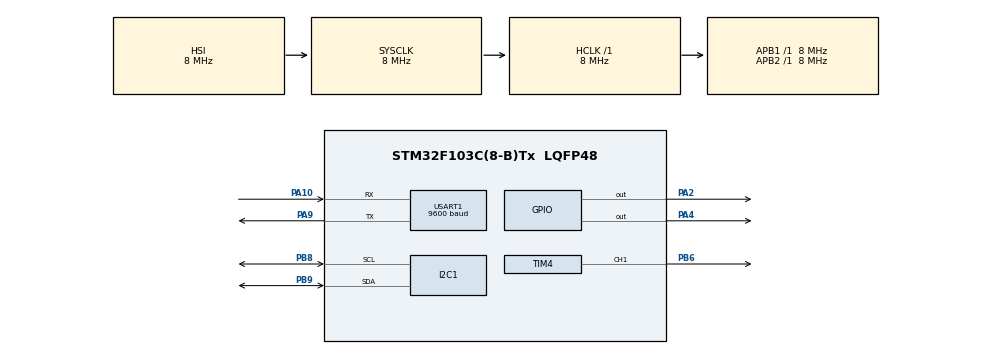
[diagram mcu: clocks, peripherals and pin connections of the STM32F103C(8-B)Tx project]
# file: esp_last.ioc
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Mcu.Family=STM32F1
Mcu.Name=STM32F103C(8-B)Tx
Mcu.Package=LQFP48
NVIC.FLASH_IRQn=true\:0\:0\:true\:false\:true\:true\:true
NVIC.I2C1_ER_IRQn=true\:0\:0\:false\:false\:true\:true\:true
NVIC.I2C1_EV_IRQn=true\:0\:0\:false\:false\:true\:true\:true
NVIC.PriorityGroup=NVIC_PRIORITYGROUP_4
NVIC.RCC_IRQn=true\:0\:0\:false\:false\:true\:true\:false
NVIC.TIM4_IRQn=true\:0\:0\:false\:false\:true\:true\:true
NVIC.USART1_IRQn=true\:0\:0\:false\:false\:true\:true\:true
PA10.Mode=Asynchronous
PA10.Signal=USART1_RX
PA13.Mode=Serial_Wire
PA13.Signal=SYS_JTMS-SWDIO
PA14.Mode=Serial_Wire
PA14.Signal=SYS_JTCK-SWCLK
PA2.Signal=GPIO_Output
PA4.Signal=GPIO_Output
PA9.Mode=Asynchronous
PA9.Signal=USART1_TX
PB6.Signal=S_TIM4_CH1
PB8.Mode=I2C
PB8.Signal=I2C1_SCL
PB9.Mode=I2C
PB9.Signal=I2C1_SDA
PD0-OSC_IN.Mode=HSE-External-Oscillator
PD0-OSC_IN.Signal=RCC_OSC_IN
PD1-OSC_OUT.Mode=HSE-External-Oscillator
PD1-OSC_OUT.Signal=RCC_OSC_OUT
ProjectManager.HeapSize=0x200
ProjectManager.StackSize=0x400
ProjectManager.TargetToolchain=MDK-ARM V5
RCC.AHBFreq_Value=8000000
RCC.APB1Freq_Value=8000000
RCC.APB1TimFreq_Value=8000000
RCC.APB2Freq_Value=8000000
RCC.APB2TimFreq_Value=8000000
RCC.HCLKFreq_Value=8000000
RCC.SYSCLKFreq_VALUE=8000000
RCC.USBFreq_Value=8000000
SH.S_TIM4_CH1.0=TIM4_CH1,PWM Generation1 CH1
TIM4.Channel-PWM\ Generation1\ CH1=TIM_CHANNEL_1
TIM4.ClockDivision=TIM_CLOCKDIVISION_DIV1
TIM4.Period=999
TIM4.Prescaler=19
TIM4.Pulse-PWM\ Generation1\ CH1=500
USART1.BaudRate=9600
USART1.VirtualMode=VM_ASYNC
VP_TIM4_VS_ClockSourceINT.Mode=Internal
board=custom

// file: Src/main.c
/* USER CODE BEGIN Header */
/**
  ******************************************************************************
  * @file           : main.c
  * @brief          : Main program body
  ******************************************************************************
  * @attention
  *
  * <h2><center>&copy; Copyright (c) 2019 STMicroelectronics.
  * All rights reserved.</center></h2>
  *
  * This software component is licensed by ST under BSD 3-Clause license,
  * the "License"; You may not use this file except in compliance with the
  * License. You may obtain a copy of the License at:
  *                        opensource.org/licenses/BSD-3-Clause
  *
  ******************************************************************************
  */
/* USER CODE END Header */

#include "main.h"

/* USER CODE BEGIN Includes */
#include "stm32f1xx_hal.h"
#include "esp8266.h"
#include "servo.h"
#include "write_lcd_func.h"
/* USER CODE END Includes */

I2C_HandleTypeDef hi2c1;

TIM_HandleTypeDef htim4;

//UART_HandleTypeDef huart1;

/* USER CODE BEGIN PV */
extern UART_HandleTypeDef huart1;
extern int complete;
/* USER CODE END PV */

void SystemClock_Config(void);
static void MX_GPIO_Init(void);
static void MX_I2C1_Init(void);
static void MX_USART1_UART_Init(void);
static void MX_TIM4_Init(void);

/* USER CODE BEGIN 0 */
extern uint8_t Rx_data;
/* USER CODE END 0 */

int main(void)
{

  /* MCU Configuration--------------------------------------------------------*/

  /* Reset of all peripherals, Initializes the Flash interface and the Systick. */
  HAL_Init();

  /* Configure the system clock */
  SystemClock_Config();

  /* Initialize all configured peripherals */
  MX_GPIO_Init();
  MX_I2C1_Init();
  MX_USART1_UART_Init();
  MX_TIM4_Init();
  /* USER CODE BEGIN 2 */
	send_intro_lcd();
	HAL_UART_Receive_IT(&huart1,	&Rx_data, 1);
	ESP_Init();
  /* USER CODE END 2 */

  /* Infinite loop */
  while (1)
  {

    /* USER CODE BEGIN 3 */
//		if(complete == 1)
		ESP_Read();
  }
  /* USER CODE END 3 */
}

void SystemClock_Config(void)
{
  RCC_OscInitTypeDef RCC_OscInitStruct = {0};
  RCC_ClkInitTypeDef RCC_ClkInitStruct = {0};

  /** Initializes the CPU, AHB and APB busses clocks
  */
  RCC_OscInitStruct.OscillatorType = RCC_OSCILLATORTYPE_HSI;
  RCC_OscInitStruct.HSIState = RCC_HSI_ON;
  RCC_OscInitStruct.HSICalibrationValue = RCC_HSICALIBRATION_DEFAULT;
  RCC_OscInitStruct.PLL.PLLState = RCC_PLL_NONE;
  if (HAL_RCC_OscConfig(&RCC_OscInitStruct) != HAL_OK)
  {
    Error_Handler();
  }
  /** Initializes the CPU, AHB and APB busses clocks
  */
  RCC_ClkInitStruct.ClockType = RCC_CLOCKTYPE_HCLK|RCC_CLOCKTYPE_SYSCLK
                              |RCC_CLOCKTYPE_PCLK1|RCC_CLOCKTYPE_PCLK2;
  RCC_ClkInitStruct.SYSCLKSource = RCC_SYSCLKSOURCE_HSI;
  RCC_ClkInitStruct.AHBCLKDivider = RCC_SYSCLK_DIV1;
  RCC_ClkInitStruct.APB1CLKDivider = RCC_HCLK_DIV1;
  RCC_ClkInitStruct.APB2CLKDivider = RCC_HCLK_DIV1;

  if (HAL_RCC_ClockConfig(&RCC_ClkInitStruct, FLASH_LATENCY_0) != HAL_OK)
  {
    Error_Handler();
  }
}

static void MX_I2C1_Init(void)
{

  hi2c1.Instance = I2C1;
  hi2c1.Init.ClockSpeed = 100000;
  hi2c1.Init.DutyCycle = I2C_DUTYCYCLE_2;
  hi2c1.Init.OwnAddress1 = 0;
  hi2c1.Init.AddressingMode = I2C_ADDRESSINGMODE_7BIT;
  hi2c1.Init.DualAddressMode = I2C_DUALADDRESS_DISABLE;
  hi2c1.Init.OwnAddress2 = 0;
  hi2c1.Init.GeneralCallMode = I2C_GENERALCALL_DISABLE;
  hi2c1.Init.NoStretchMode = I2C_NOSTRETCH_DISABLE;
  if (HAL_I2C_Init(&hi2c1) != HAL_OK)
  {
    Error_Handler();
  }

}

static void MX_TIM4_Init(void)
{

  TIM_ClockConfigTypeDef sClockSourceConfig = {0};
  TIM_MasterConfigTypeDef sMasterConfig = {0};
  TIM_OC_InitTypeDef sConfigOC = {0};

  htim4.Instance = TIM4;
  htim4.Init.Prescaler = 159;
  htim4.Init.CounterMode = TIM_COUNTERMODE_UP;
  htim4.Init.Period = 999;
  htim4.Init.ClockDivision = TIM_CLOCKDIVISION_DIV1;
  htim4.Init.AutoReloadPreload = TIM_AUTORELOAD_PRELOAD_DISABLE;
  if (HAL_TIM_Base_Init(&htim4) != HAL_OK)
  {
    Error_Handler();
  }
  sClockSourceConfig.ClockSource = TIM_CLOCKSOURCE_INTERNAL;
  if (HAL_TIM_ConfigClockSource(&htim4, &sClockSourceConfig) != HAL_OK)
  {
    Error_Handler();
  }
  if (HAL_TIM_PWM_Init(&htim4) != HAL_OK)
  {
    Error_Handler();
  }
  sMasterConfig.MasterOutputTrigger = TIM_TRGO_RESET;
  sMasterConfig.MasterSlaveMode = TIM_MASTERSLAVEMODE_DISABLE;
  if (HAL_TIMEx_MasterConfigSynchronization(&htim4, &sMasterConfig) != HAL_OK)
  {
    Error_Handler();
  }
  sConfigOC.OCMode = TIM_OCMODE_PWM1;
  sConfigOC.Pulse = 500;
  sConfigOC.OCPolarity = TIM_OCPOLARITY_HIGH;
  sConfigOC.OCFastMode = TIM_OCFAST_DISABLE;
  if (HAL_TIM_PWM_ConfigChannel(&htim4, &sConfigOC, TIM_CHANNEL_1) != HAL_OK)
  {
    Error_Handler();
  }
  HAL_TIM_MspPostInit(&htim4);

}

static void MX_USART1_UART_Init(void)
{

  huart1.Instance = USART1;
  huart1.Init.BaudRate = 9600;
  huart1.Init.WordLength = UART_WORDLENGTH_8B;
  huart1.Init.StopBits = UART_STOPBITS_1;
  huart1.Init.Parity = UART_PARITY_NONE;
  huart1.Init.Mode = UART_MODE_TX_RX;
  huart1.Init.HwFlowCtl = UART_HWCONTROL_NONE;
  huart1.Init.OverSampling = UART_OVERSAMPLING_16;
  if (HAL_UART_Init(&huart1) != HAL_OK)
  {
    Error_Handler();
  }

}

static void MX_GPIO_Init(void)
{
  GPIO_InitTypeDef GPIO_InitStruct = {0};

  /* GPIO Ports Clock Enable */
  __HAL_RCC_GPIOD_CLK_ENABLE();
  __HAL_RCC_GPIOA_CLK_ENABLE();
  __HAL_RCC_GPIOB_CLK_ENABLE();

  /*Configure GPIO pin Output Level */
  HAL_GPIO_WritePin(GPIOA, GPIO_PIN_2|GPIO_PIN_4, GPIO_PIN_RESET);

  /*Configure GPIO pins : PA2 PA4 */
  GPIO_InitStruct.Pin = GPIO_PIN_2|GPIO_PIN_4;
  GPIO_InitStruct.Mode = GPIO_MODE_OUTPUT_PP;
  GPIO_InitStruct.Pull = GPIO_NOPULL;
  GPIO_InitStruct.Speed = GPIO_SPEED_FREQ_LOW;
  HAL_GPIO_Init(GPIOA, &GPIO_InitStruct);

}

void Error_Handler(void)
{
}

/************************ (C) COPYRIGHT STMicroelectronics *****END OF FILE****/
